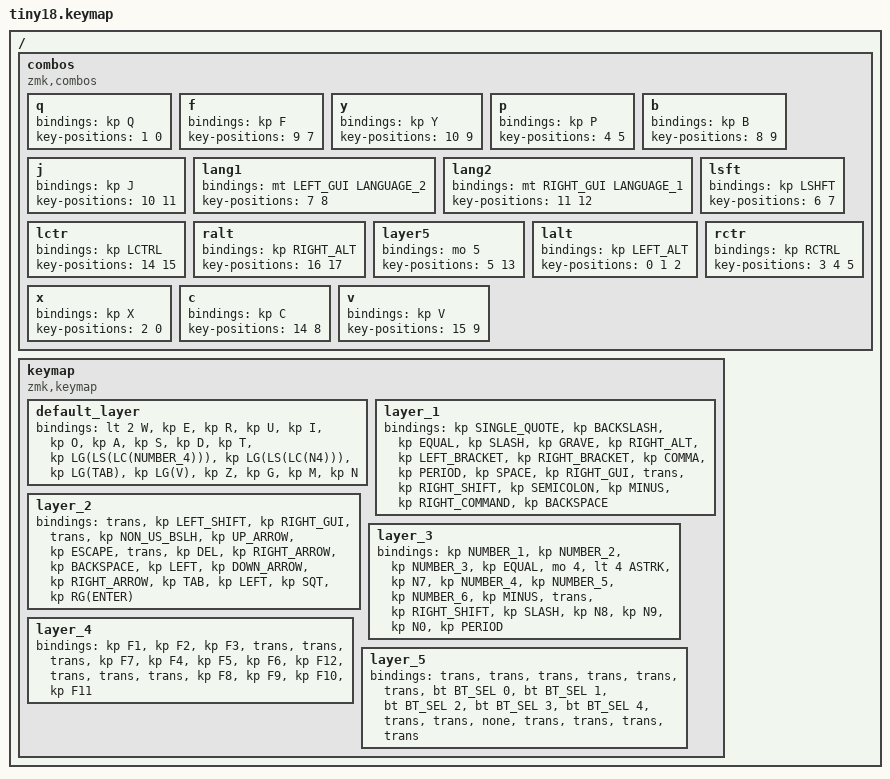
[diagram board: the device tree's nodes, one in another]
#include <input/processors.dtsi>
#include <dt-bindings/zmk/input_transform.h>
#include <zephyr/dt-bindings/input/input-event-codes.h>
#include <behaviors.dtsi>
#include <dt-bindings/zmk/bt.h>
#include <dt-bindings/zmk/keys.h>

/ {
    combos {
        compatible = "zmk,combos";

        q {
            bindings = <&kp Q>;
            key-positions = <1 0>;
        };

        f {
            bindings = <&kp F>;
            key-positions = <9 7>;
        };

        y {
            bindings = <&kp Y>;
            key-positions = <10 9>;
        };

        p {
            bindings = <&kp P>;
            key-positions = <4 5>;
        };

        b {
            bindings = <&kp B>;
            key-positions = <8 9>;
        };

        j {
            bindings = <&kp J>;
            key-positions = <10 11>;
        };

        lang1 {
            bindings = <&mt LEFT_GUI LANGUAGE_2>;
            key-positions = <7 8>;
        };

        lang2 {
            bindings = <&mt RIGHT_GUI LANGUAGE_1>;
            key-positions = <11 12>;
        };

        lsft {
            bindings = <&kp LSHFT>;
            key-positions = <6 7>;
        };

        lctr {
            bindings = <&kp LCTRL>;
            key-positions = <14 15>;
        };

        ralt {
            bindings = <&kp RIGHT_ALT>;
            key-positions = <16 17>;
        };

        layer5 {
            bindings = <&mo 5>;
            key-positions = <5 13>;
        };

        lalt {
            bindings = <&kp LEFT_ALT>;
            key-positions = <0 1 2>;
        };

        rctr {
            bindings = <&kp RCTRL>;
            key-positions = <3 4 5>;
        };

        x {
            bindings = <&kp X>;
            key-positions = <2 0>;
        };

        c {
            bindings = <&kp C>;
            key-positions = <14 8>;
        };

        v {
            bindings = <&kp V>;
            key-positions = <15 9>;
        };
    };

    keymap {
        compatible = "zmk,keymap";

        default_layer {
            bindings = <
&lt 2 W  &kp E  &kp R  &kp U  &kp I  &kp O  &kp A  &kp S  &kp D  &kp T  &kp LG(LS(LC(NUMBER_4)))  &kp LG(LS(LC(N4)))  &kp LG(TAB)  &kp LG(V)  &kp Z  &kp G  &kp M  &kp N
            >;
        };

        layer_1 {
            bindings = <
&kp SINGLE_QUOTE  &kp BACKSLASH  &kp EQUAL  &kp SLASH  &kp GRAVE  &kp RIGHT_ALT  &kp LEFT_BRACKET  &kp RIGHT_BRACKET  &kp COMMA  &kp PERIOD  &kp SPACE  &kp RIGHT_GUI  &trans  &kp RIGHT_SHIFT  &kp SEMICOLON  &kp MINUS  &kp RIGHT_COMMAND  &kp BACKSPACE
            >;
        };

        layer_2 {
            bindings = <
&trans  &kp LEFT_SHIFT  &kp RIGHT_GUI  &trans  &kp NON_US_BSLH  &kp UP_ARROW  &kp ESCAPE  &trans  &kp DEL  &kp RIGHT_ARROW  &kp BACKSPACE  &kp LEFT  &kp DOWN_ARROW  &kp RIGHT_ARROW  &kp TAB  &kp LEFT  &kp SQT  &kp RG(ENTER)
            >;
        };

        layer_3 {
            bindings = <
&kp NUMBER_1  &kp NUMBER_2  &kp NUMBER_3  &kp EQUAL  &mo 4  &lt 4 ASTRK  &kp N7  &kp NUMBER_4  &kp NUMBER_5  &kp NUMBER_6  &kp MINUS  &trans  &kp RIGHT_SHIFT  &kp SLASH  &kp N8  &kp N9  &kp N0  &kp PERIOD
            >;
        };

        layer_4 {
            bindings = <
&kp F1  &kp F2  &kp F3  &trans  &trans  &trans  &kp F7  &kp F4  &kp F5  &kp F6  &kp F12  &trans  &trans  &trans  &kp F8  &kp F9  &kp F10  &kp F11
            >;
        };

        layer_5 {
            bindings = <
&trans  &trans  &trans  &trans  &trans  &trans  &bt BT_SEL 0  &bt BT_SEL 1  &bt BT_SEL 2  &bt BT_SEL 3  &bt BT_SEL 4  &trans  &trans  &none  &trans  &trans  &trans  &trans
            >;
        };
    };
};
